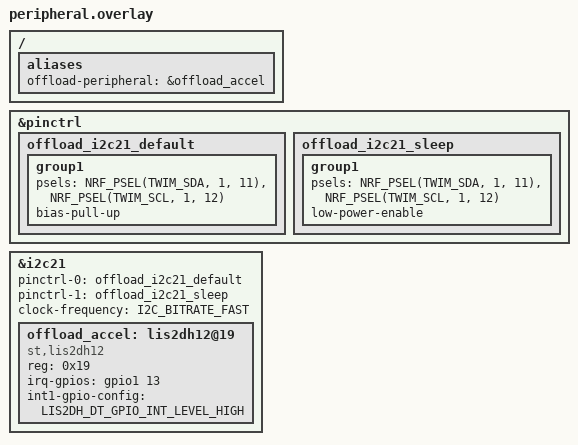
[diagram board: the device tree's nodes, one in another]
/*
 * Copyright (c) 2026 Nordic Semiconductor ASA
 *
 * SPDX-License-Identifier: LicenseRef-Nordic-5-Clause
 */

/*
 * LIS2DH12 accelerometer on TWIM (i2c21), applied to the core that runs the
 * workload: the FLPR when offloaded, the M33 in the local baseline.
 *
 * Wiring on the nRF54LM20 DK:
 *   SDA  P1.11   (the TWIM pins Nordic's nPM13xx samples use on this DK)
 *   SCL  P1.12
 *   INT1 P1.13   (a free GPIO chosen for this sample; not checked against the
 *                 DK schematic, move it if your board uses the pin)
 *   SA0/SDO high gives address 0x19, which most breakout boards default to; use
 *   0x18 if SA0 is tied low. The internal pull-ups are weak for 400 kHz; breakout
 *   boards carry their own. Without them, use I2C_BITRATE_STANDARD.
 *
 * INT1 is level-triggered. The driver masks the pin in its interrupt callback and
 * unmasks it after the handler has read the sample, without checking the pin.
 * With a level trigger, a sample that arrives while the pin is masked still
 * fires on unmask; with an edge trigger it would be missed, and data-ready would
 * then stay high with no further edge.
 */

#include <zephyr/dt-bindings/i2c/i2c.h>
#include <zephyr/dt-bindings/sensor/lis2dh.h>

/ {
	aliases {
		offload-peripheral = &offload_accel;
	};
};

&pinctrl {
	offload_i2c21_default: offload_i2c21_default {
		group1 {
			psels = <NRF_PSEL(TWIM_SDA, 1, 11)>,
				<NRF_PSEL(TWIM_SCL, 1, 12)>;
			bias-pull-up;
		};
	};

	offload_i2c21_sleep: offload_i2c21_sleep {
		group1 {
			psels = <NRF_PSEL(TWIM_SDA, 1, 11)>,
				<NRF_PSEL(TWIM_SCL, 1, 12)>;
			low-power-enable;
		};
	};
};

&i2c21 {
	status = "okay";
	pinctrl-0 = <&offload_i2c21_default>;
	pinctrl-1 = <&offload_i2c21_sleep>;
	pinctrl-names = "default", "sleep";
	clock-frequency = <I2C_BITRATE_FAST>;

	offload_accel: lis2dh12@19 {
		compatible = "st,lis2dh12", "st,lis2dh";
		reg = <0x19>;
		irq-gpios = <&gpio1 13 GPIO_ACTIVE_HIGH>;
		int1-gpio-config = <LIS2DH_DT_GPIO_INT_LEVEL_HIGH>;
	};
};
